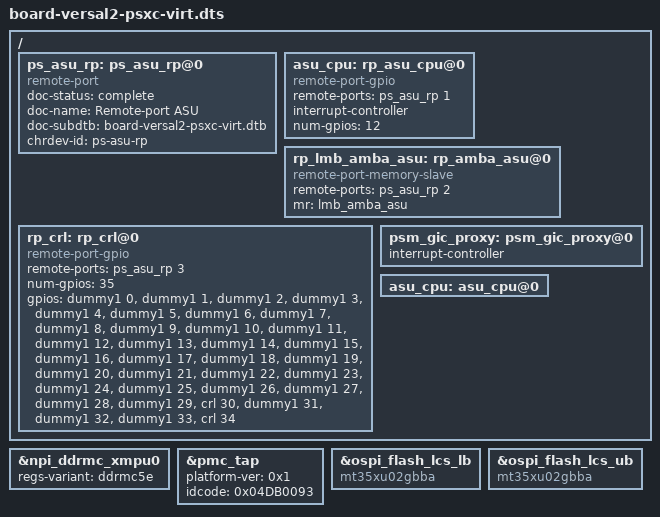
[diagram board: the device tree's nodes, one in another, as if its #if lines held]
/*
 * Versal Gen 2 Virtual PSXC board device tree.
 *
 * Copyright (c) 2023-2024 Advanced Micro Devices Inc.
 * All rights reserved.
 *
 * Redistribution and use in source and binary forms, with or without
 * modification, are permitted provided that the following conditions are met:
 *     * Redistributions of source code must retain the above copyright
 *       notice, this list of conditions and the following disclaimer.
 *     * Redistributions in binary form must reproduce the above copyright
 *       notice, this list of conditions and the following disclaimer in the
 *       documentation and/or other materials provided with the distribution.
 *     * Neither the name of the <organization> nor the
 *       names of its contributors may be used to endorse or promote products
 *       derived from this software without specific prior written permission.
 *
 * THIS SOFTWARE IS PROVIDED BY THE COPYRIGHT HOLDERS AND CONTRIBUTORS "AS IS" AND
 * ANY EXPRESS OR IMPLIED WARRANTIES, INCLUDING, BUT NOT LIMITED TO, THE IMPLIED
 * WARRANTIES OF MERCHANTABILITY AND FITNESS FOR A PARTICULAR PURPOSE ARE
 * DISCLAIMED. IN NO EVENT SHALL <COPYRIGHT HOLDER> BE LIABLE FOR ANY
 * DIRECT, INDIRECT, INCIDENTAL, SPECIAL, EXEMPLARY, OR CONSEQUENTIAL DAMAGES
 * (INCLUDING, BUT NOT LIMITED TO, PROCUREMENT OF SUBSTITUTE GOODS OR SERVICES;
 * LOSS OF USE, DATA, OR PROFITS; OR BUSINESS INTERRUPTION) HOWEVER CAUSED AND
 * ON ANY THEORY OF LIABILITY, WHETHER IN CONTRACT, STRICT LIABILITY, OR TORT
 * (INCLUDING NEGLIGENCE OR OTHERWISE) ARISING IN ANY WAY OUT OF THE USE OF THIS
 * SOFTWARE, EVEN IF ADVISED OF THE POSSIBILITY OF SUCH DAMAGE.
 */

#ifndef NUM_APUS
#define NUM_APUS 8
#endif

#define NUM_APUS_PER_CLUSTER 2

/* RPU configuration.  */

#ifndef NUM_RPUS
#define NUM_RPUS 10
#endif

#define VERSAL2_DEV
#define VERSAL_NPI_GENERIC
#define VERSAL_PSX
#define VERSAL_NET
#define VERSAL_NPI_OVERRIDE

#define MM_DDRMC_XMPU_OFFSET 0x12000

/* TODO: Add GIC interrupt redirection support.  */
#define APU_GIC_INTERRUPT_TARGET_STEM cpu
#define RPU_GIC_INTERRUPT_TARGET_STEM rpu_cpu

#define APU_CPU_MODEL "cortex-a78-arm-cpu"
#define RPU_CPU_MODEL "cortex-r52-arm-cpu"

#include "board-versal-ps-virt.dts"
#include "versal-psx.dtsi"
#include "versal-net-psmx.dtsi"
#include "versal-psx-rpu.dtsi"
#include "versal-net-boot-init.dtsi"
#include "versal-net-hnic.dtsi"
#include "versal2-pmx-shared-overlay.dtsi"
#include "versal-pmx-system-overlay.dtsi"
#include "versal-psx-shared-overlay.dtsi"
#include "versal2-psx-shared-overlay.dtsi"
#include "versal2-icnt.dtsi"
#include "versal2-rams.dtsi"
#include "versal2-mmi.dtsi"
#include "versal2-pmxc-system-overlay.dtsi"
#include "versal2-asu.dtsi"

#ifndef VERSAL_NET_APU_CPU_FREQ
 #define VERSAL_NET_APU_CPU_FREQ 2720000
#endif

#define SET_CPU_FREQ(n, f)					\
&cpu ## n {							\
	generic-timer-frequency = <f>;				\
}

SET_CPU_FREQ(0, VERSAL_NET_APU_CPU_FREQ);
SET_CPU_FREQ(1, VERSAL_NET_APU_CPU_FREQ);
SET_CPU_FREQ(2, VERSAL_NET_APU_CPU_FREQ);
SET_CPU_FREQ(3, VERSAL_NET_APU_CPU_FREQ);
#if (NUM_APUS >= 8)
SET_CPU_FREQ(4, VERSAL_NET_APU_CPU_FREQ);
SET_CPU_FREQ(5, VERSAL_NET_APU_CPU_FREQ);
SET_CPU_FREQ(6, VERSAL_NET_APU_CPU_FREQ);
SET_CPU_FREQ(7, VERSAL_NET_APU_CPU_FREQ);
#endif

#define RPU_CTRL_FIXUP(c, f, s) \
&rpu_ctrl_ ## c { \
	tcm-mr = <&glue(s_axi_tcm_, c)>; \
}; \
&rpu_ctrl_ ## c ## 0 { \
	core = <&glue(rpu_cpu, f)>; \
	tcm-mr = <&glue(tcm_core, f)>; \
}; \
&rpu_ctrl_ ## c ## 1 { \
	core = <&glue(rpu_cpu, s)>; \
	tcm-mr = <&glue(tcm_core, s)>; \
}

RPU_CTRL_FIXUP(a, 0, 1);
RPU_CTRL_FIXUP(b, 2, 3);
#if (NUM_RPUS >= 8)
RPU_CTRL_FIXUP(c, 4, 5);
RPU_CTRL_FIXUP(d, 6, 7);
#endif
#if (NUM_RPUS >= 10)
RPU_CTRL_FIXUP(e, 8, 9);
#endif

&npi_ddrmc_xmpu0 {
	regs-variant = "ddrmc5e";
};

&pmc_tap {
	platform-ver = <0x1>;
	/*
	* Default device : xc2ve3858
	*/
	idcode = <0x04DB0093>;
};

#ifdef MULTI_ARCH
/{
	ps_asu_rp: ps_asu_rp@0 {
		doc-status = "complete";
		doc-name = "Remote-port ASU";
		doc-subdtb = "board-versal2-psxc-virt.dtb";
		compatible = "remote-port";
		chrdev-id = "ps-asu-rp";
	};
	asu_cpu: rp_asu_cpu@0 {
		compatible = "remote-port-gpio";
		remote-ports = <&ps_asu_rp 1>;
		#interrupt-cells = <1>;
		interrupt-controller;
		num-gpios = <12>;
	};
	rp_lmb_amba_asu: rp_amba_asu@0 {
		compatible = "remote-port-memory-slave";
		remote-ports = <&ps_asu_rp 2>;
		mr = <&lmb_amba_asu>;
	};
	rp_crl: rp_crl@0 {
		compatible = "remote-port-gpio";
		remote-ports = <&ps_asu_rp 3>;
		#gpio-cells = <1>;
		num-gpios = <35>;
		gpios = <
			 &dummy1 0
			 &dummy1 1
			 &dummy1 2
			 &dummy1 3
			 &dummy1 4
			 &dummy1 5
			 &dummy1 6
			 &dummy1 7
			 &dummy1 8
			 &dummy1 9
			 &dummy1 10
			 &dummy1 11
			 &dummy1 12
			 &dummy1 13
			 &dummy1 14
			 &dummy1 15
			 &dummy1 16
			 &dummy1 17
			 &dummy1 18
			 &dummy1 19
			 &dummy1 20
			 &dummy1 21
			 &dummy1 22
			 &dummy1 23
			 &dummy1 24
			 &dummy1 25
			 &dummy1 26
			 &dummy1 27
			 &dummy1 28
			 &dummy1 29
			 &crl 30
			 &dummy1 31
			 &dummy1 32
			 &dummy1 33
			 &crl 34
		>;
	};
};
#endif

/ {
	/* TODO: remove reference to these blocks, and then remove the block
	 * below.  */
	psm_gic_proxy: psm_gic_proxy@0 {
		#interrupt-cells = <0x03>;
		interrupt-controller;
	};

#ifndef MULTI_ARCH
	asu_cpu: asu_cpu@0 {
		#interrupt-cells = <1>;
	};
#endif
};

&ospi_flash_lcs_lb {
	compatible = "mt35xu02gbba";
};

&ospi_flash_lcs_ub {
	compatible = "mt35xu02gbba";
};
